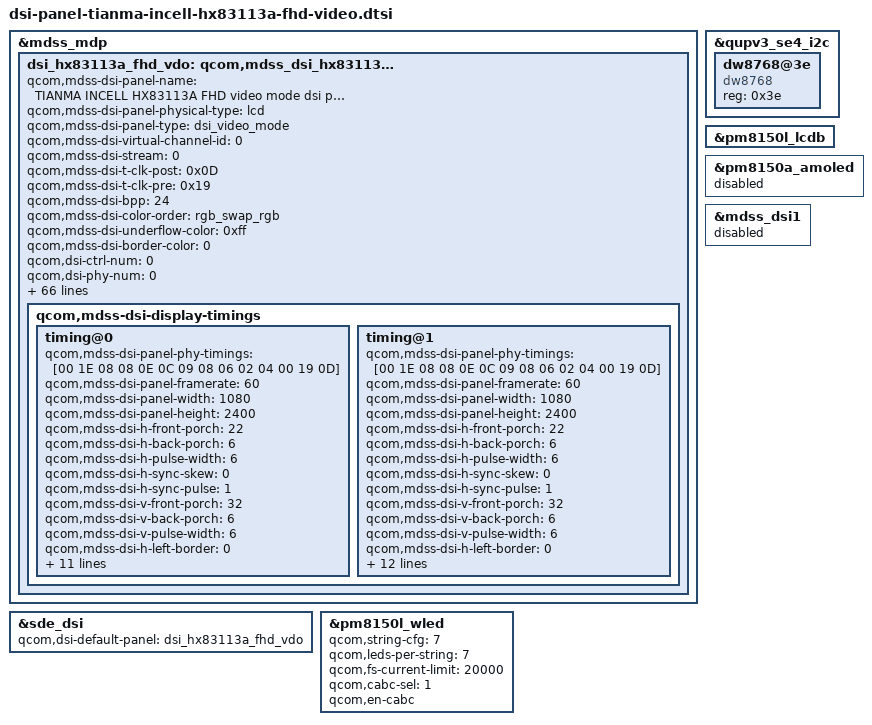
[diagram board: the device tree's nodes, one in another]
/* Copyright (c) 2014, Code Aurora Forum. All rights reserved.
 *
 * This program is free software; you can redistribute it and/or modify
 * it under the terms of the GNU General Public License version 2 and
 * only version 2 as published by the Free Software Foundation.
 *
 * This program is distributed in the hope that it will be useful,
 * but WITHOUT ANY WARRANTY; without even the implied warranty of
 * MERCHANTABILITY or FITNESS FOR A PARTICULAR PURPOSE.  See the
 * GNU General Public License for more details.
 */

&mdss_mdp {
	dsi_hx83113a_fhd_vdo: qcom,mdss_dsi_hx83113a_fhd_vdo {
		//qcom,cont-splash-enabled;
		qcom,mdss-dsi-panel-name = "TIANMA INCELL HX83113A FHD video mode dsi panel";
		//qcom,mdss-dsi-panel-controller = <&mdss_dsi0>;
		qcom,mdss-dsi-panel-physical-type = "lcd";
		qcom,mdss-dsi-panel-type = "dsi_video_mode";
		//qcom,mdss-dsi-panel-destination = "display_1";
		qcom,mdss-dsi-virtual-channel-id = <0>;
		qcom,mdss-dsi-stream = <0>;
		qcom,mdss-dsi-t-clk-post = <0x0D>;
		qcom,mdss-dsi-t-clk-pre = <0x19>;
		qcom,mdss-dsi-bpp = <24>;
		qcom,mdss-dsi-color-order = "rgb_swap_rgb";
		qcom,mdss-dsi-underflow-color = <0xff>;
		qcom,mdss-dsi-border-color = <0>;
		qcom,dsi-ctrl-num = <0>;
		qcom,dsi-phy-num = <0>;
		qcom,dsi-select-clocks = "mux_byte_clk0", "mux_pixel_clk0",
								"src_byte_clk0", "src_pixel_clk0",
								"shadow_byte_clk0", "shadow_pixel_clk0";
		//qcom,esd-check-enabled;
		qcom,mdss-dsi-traffic-mode = "non_burst_sync_pulse";
		qcom,mdss-dsi-lane-map = "lane_map_0123";
		qcom,mdss-dsi-dma-trigger = "trigger_sw";
		qcom,mdss-dsi-mdp-trigger = "none";
		qcom,mdss-dsi-bllp-eof-power-mode;
		qcom,mdss-dsi-bllp-power-mode;
		qcom,ulps-enabled;
		qcom,mdss-dsi-lane-0-state;
		qcom,mdss-dsi-lane-1-state;
		qcom,mdss-dsi-lane-2-state;
		qcom,mdss-dsi-lane-3-state;
		qcom,mdss-dsi-tx-eot-append;

		qcom,mdss-dsi-bl-min-level = <1>;
		qcom,mdss-dsi-bl-max-level = <2047>;
		qcom,mdss-dsi-bl-pmic-control-type = "bl_ctrl_wled";
		qcom,mdss-dsi-reset-sequence = <0 1>, <1 11>;
		lge,incell-panel;
		lge,panel-on-pin-seq = <0 1 5>;
		lge,panel-off-pin-seq = <0 0 1>;
		lge,mdss-dsi-lp11-off;

		//qcom,mdss-dsi-te-pin-select = <1>;
		//qcom,mdss-dsi-te-dcs-command = <1>;
		//qcom,mdss-dsi-te-check-enable;
		//qcom,mdss-dsi-te-using-te-pin;
		qcom,mdss-dsi-lp11-init;
		qcom,mdss-dsi-wr-mem-start = <0x2c>;
		qcom,mdss-dsi-wr-mem-continue = <0x3c>;

		qcom,mdss-pan-physical-width-dimension = <68>;
		qcom,mdss-pan-physical-height-dimension = <152>;

		lge,blmap-size = <256>;
		lge,blmap = <
			0 31 31 31 31 31 31 31 31 31 31 33 35 37 39 41 43 45 47 49                    // 19
			51 53 55 58 60 62 64 66 68 70 72 74 76 78 80 83 85 87 89 91                    // 39
			93 95 97 99 101 103 105 107 110 112 114 116 118 120 122 124 126 128 130 132                    // 59
			135 142 150 158 166 174 182 190 198 206 214 222 230 238 246 254 262 270 278 286                    // 79
			294 302 310 318 326 334 342 350 358 366 374 382 390 398 406 414 422 430 438 446                    // 99
			454 462 470 478 486 494 502 510 518 532 546 560 574 588 602 616 630 645 659 673                    // 119
			687 701 715 729 743 758 772 786 800 814 828 842 856 871 885 899 913 927 941 955                    // 139
			969 984 998 1012 1026 1040 1054 1068 1082 1097 1111 1125 1139 1153 1167 1181 1195 1210 1231 1253                    // 159
			1274 1296 1317 1339 1360 1382 1403 1425 1447 1468 1490 1511 1533 1554 1576 1597 1619 1641 1662 1684                    // 179
			1705 1727 1748 1770 1791 1813 1834 1856 1878 1899 1921 1942 1964 1985 2007 2028 2050 2072 2093 2115                    // 199
			2136 2158 2179 2201 2222 2244 2266 2295 2325 2354 2384 2413 2443 2473 2502 2532 2561 2591 2620 2650                    // 219
			2680 2709 2739 2768 2798 2827 2857 2887 2916 2946 2975 3005 3034 3064 3094 3123 3153 3182 3212 3241                    // 239
			3271 3301 3330 3360 3389 3419 3448 3478 3508 3537 3567 3596 3626 3655 3685 3715                    // 255
		>;

		lge,use-color-manager;
		lge,use-color-manager-oled;
		lge,color-manager-default-status = <1>;
		lge,mdss-dsi-color-manager-mode-table = <0 1>, <1 1>, <2 1>, <3 1>;
		lge,digital-gamma-absent;

		/* Screen Color Control */
		lge,rgb-lut = [
			15 01 00 00 00 00 02 BD 00
			15 01 00 00 00 00 02 C1 01
			15 01 00 00 00 00 02 BD 01
			39 01 00 00 00 00 3B C1 00 04 08 0C 10 14 18 1C 1F 23 27 2B 2F 33 37 3B 3F 43 47 4B 53 5B 62 6A 72 7A 82 8A 92 9A A1 A9 B1 B9 C1 C9 D1 D9 E0 E8 F0 F4 F6 F8 FA FB FF FF FF FF FF FF FF FF FF FF FF FF
			15 01 00 00 00 00 02 BD 02
			39 01 00 00 00 00 3B C1 00 04 08 0C 10 14 18 1C 20 24 28 2C 30 34 38 3C 40 44 48 4C 54 5C 64 6C 74 7C 84 8C 94 9C A4 AC B4 BC C4 CC D4 DC E4 EC F4 F8 FA FC FE FF FF FF FF FF FF FF FF FF FF FF FF FF
			15 01 00 00 00 00 02 BD 03
			39 01 00 00 00 00 3B C1 00 04 07 0B 0E 12 16 19 1D 21 24 28 2B 2F 33 36 3A 3E 41 45 4C 53 5B 62 69 70 78 7F 86 8D 95 9C A3 AA B2 B9 C0 C7 CF D6 DD E1 E2 E4 E6 E7 FF FF FF FF FF FF FF FF FF FF FF FF
		];
		lge,rgb-lut-state = "dsi_hs_mode";

		lge,mdss-dsi-disp-ctrl-command-1 = [
			15 01 00 00 00 00 02 CE 25
		];
		lge,mdss-dsi-disp-ctrl-command-1-state = "dsi_hs_mode";

		lge,mdss-dsi-saturation-command = [
			39 01 00 00 00 00 3D E6 40 2A 1E 00 AA 3A 11 26 00 AA DD D6 F0 D4 55 FF F0 00 00 A5 00 2A 00 00 AA 00 33 33 00 AA 00 00 00 00 AA 00 00 00 00 AA 00 00 00 00 AA DD D0 F0 FF 55 00 00 00 00 AA 66 33 2A 00 AA
		];
		lge,mdss-dsi-saturation-command-state = "dsi_hs_mode";

		lge,mdss-dsi-hue-command = [
			15 01 00 00 00 00 02 BD 00
			39 01 00 00 00 00 0E E5 06 FF FE FE FF 06 00 FE 00 FE 11 1C 05
		];
		lge,mdss-dsi-hue-command-state = "dsi_hs_mode";

		lge,mdss-dsi-cm-natural = [
			15 01 00 00 00 00 02 BD 00
			39 01 00 00 00 00 0E E5 06 FF FE FE FF 06 00 FE 00 FE 11 1C 05
			39 01 00 00 00 00 3D E6 40 2A 1E 00 AA 3A 11 26 00 AA DD D6 F0 D4 55 FF F0 00 00 A5 00 2A 00 00 AA 00 33 33 00 AA 00 00 00 00 AA 00 00 00 00 AA 00 00 00 00 AA DD D0 F0 FF 55 00 00 00 00 AA 66 33 2A 00 AA
			15 01 00 00 00 00 02 BD 00
			15 01 00 00 00 00 02 C1 01
			15 01 00 00 00 00 02 BD 01
			39 01 00 00 00 00 3B C1 00 04 08 0C 10 14 18 1C 1F 23 27 2B 2F 33 37 3B 3F 43 47 4B 53 5B 62 6A 72 7A 82 8A 92 9A A1 A9 B1 B9 C1 C9 D1 D9 E0 E8 F0 F4 F6 F8 FA FB FF FF FF FF FF FF FF FF FF FF FF FF
			15 01 00 00 00 00 02 BD 02
			39 01 00 00 00 00 3B C1 00 04 08 0C 10 14 18 1C 20 24 28 2C 30 34 38 3C 40 44 48 4C 54 5C 64 6C 74 7C 84 8C 94 9C A4 AC B4 BC C4 CC D4 DC E4 EC F4 F8 FA FC FE FF FF FF FF FF FF FF FF FF FF FF FF FF
			15 01 00 00 00 00 02 BD 03
			39 01 00 00 00 00 3B C1 00 04 07 0B 0E 12 16 19 1D 21 24 28 2B 2F 33 36 3A 3E 41 45 4C 53 5B 62 69 70 78 7F 86 8D 95 9C A3 AA B2 B9 C0 C7 CF D6 DD E1 E2 E4 E6 E7 FF FF FF FF FF FF FF FF FF FF FF FF
		];
		lge,mdss-dsi-cm-natural-state = "dsi_hs_mode";

		lge,mdss-dsi-cm-vivid = [
			15 01 00 00 00 00 02 BD 00
			39 01 00 00 00 00 0E E5 06 FF FE FE FF 06 00 FE 00 FE 11 1C 05
			39 01 00 00 00 00 3D E6 70 4E 30 00 AA 60 40 30 00 AA 60 60 38 00 AA 60 60 20 00 AA 60 7A 28 00 AA 40 73 50 00 AA 10 20 10 00 AA 08 10 08 00 AA 07 0E 07 00 AA E5 E0 F8 FF 55 18 30 18 00 AA 80 78 42 00 AA
			15 01 00 00 00 00 02 BD 00
			15 01 00 00 00 00 02 C1 01
			39 01 00 00 00 00 02 BD 01
			39 01 00 00 00 00 3B C1 00 04 08 0C 10 14 18 1C 20 24 28 2C 30 34 38 3C 3F 43 47 4B 53 5B 63 6B 73 7B 83 8B 93 9B A3 AB B3 BB C2 CA D2 DA E2 EA F2 F6 F8 FA FC FD FF FF FF FF FF FF FF FF FF FF FF FF
			39 01 00 00 00 00 02 BD 02
			39 01 00 00 00 00 3B C1 00 04 08 0C 10 14 18 1C 20 24 28 2C 30 34 38 3C 40 44 48 4C 54 5C 64 6C 74 7C 84 8C 94 9C A4 AC B4 BC C4 CC D4 DC E4 EC F4 F8 FA FC FE FF FF FF FF FF FF FF FF FF FF FF FF FF
			39 01 00 00 00 00 02 BD 03
			39 01 00 00 00 00 3B C1 00 04 08 0B 0F 13 17 1B 1E 22 26 2A 2E 32 35 39 3D 41 45 48 50 58 5F 67 6F 76 7E 85 8D 95 9C A4 AC B3 BB C2 CA D2 D9 E1 E9 EC EE F0 F2 F3 FF FF FF FF FF FF FF FF FF FF FF FF
		];
		lge,mdss-dsi-cm-vivid-state = "dsi_hs_mode";

		/* Video Enahnacement */
		lge,mdss-dsi-ve-on-command = [
			39 01 00 00 00 00 3D E6 70 4E 30 00 AA 60 40 30 00 AA 60 60 38 00 AA 60 60 20 00 AA 60 7A 28 00 AA 40 73 50 00 AA 10 20 10 00 AA 08 10 08 00 AA 07 0E 07 00 AA E5 E0 F8 FF 55 18 30 18 00 AA 80 78 42 00 AA
			15 01 00 00 00 00 02 CE 25
			15 01 00 00 00 00 02 BD 02
			39 01 00 00 00 00 24 E4 00 3F 04 00 00 04 40 00 40 80 00 00 00 90 03 00 08 00 10 08 04 04 3B 10 38 10 01 01 01 01 00 00 00 01 14
			15 01 00 00 00 00 02 BD 00
			39 01 00 00 00 00 05 E4 3D 03 41 90
		];
		lge,mdss-dsi-ve-on-command-state = "dsi_hs_mode";

		lge,mdss-dsi-ve-off-command = [
			15 01 00 00 00 00 02 BD 00
			39 01 00 00 00 00 02 E4 2D
		];
		lge,mdss-dsi-ve-off-command-state = "dsi_hs_mode";

		qcom,mdss-dsi-display-timings {
			timing@0{
				qcom,mdss-dsi-panel-phy-timings = [00 1E 08 08 0E 0C 09 08 06 02 04 00 19 0D];
				qcom,mdss-dsi-panel-framerate = <60>;
				qcom,mdss-dsi-panel-width = <1080>;
				qcom,mdss-dsi-panel-height = <2400>;
				qcom,mdss-dsi-h-front-porch = <22>;
				qcom,mdss-dsi-h-back-porch = <6>;
				qcom,mdss-dsi-h-pulse-width = <6>;
				qcom,mdss-dsi-h-sync-skew = <0>;
				qcom,mdss-dsi-h-sync-pulse = <1>;
				qcom,mdss-dsi-v-front-porch = <32>;
				qcom,mdss-dsi-v-back-porch = <6>;
				qcom,mdss-dsi-v-pulse-width = <6>;
				qcom,mdss-dsi-h-left-border = <0>;
				qcom,mdss-dsi-h-right-border = <0>;
				qcom,mdss-dsi-v-top-border = <0>;
				qcom,mdss-dsi-v-bottom-border = <0>;
				qcom,display-topology = <1 0 1>;
				qcom,default-topology-index = <0>;

				qcom,mdss-dsi-on-command = [
					39 01 00 00 00 00 04 // 10
					B9 83 11 3A

					15 01 00 00 00 00 02 // 11
					BB 03

					39 01 00 00 00 00 0C // 12
					B1 4C 1F 1F 85 80 BC 9E 3C 1E 01 01

					39 01 00 00 00 00 11 // 13
					B2 00 33 88 90 60 00 0A 1E 00 04 00 D2 11 11 00 00

					39 01 00 00 00 00 1E // 14
					B4 9D 28 9D 28 9D 28 06 CA 06 CA 06 CA 06 CA 00 00 08 09 00 14 00 0D 07 0E 00 00 00 00 8D

					15 01 00 00 00 00 02 // 15
					E9 C8

					15 01 00 00 00 00 02 // 16
					BF 04

					15 01 00 00 00 00 02 // 17
					E9 3F

					39 01 00 00 00 00 09 // 18
					C0 23 23 44 FF 12 1A 00 03

					// 19 deleted

					39 01 00 00 00 00 06 // 20
					C9 00 00 09 60 00

					39 01 00 00 00 00 08 // 21
					CB 5F 19 10 06 00 EE 04

					15 01 00 00 00 00 02 // 22
					CC 0A

					39 01 00 00 00 00 27 // 23
					D3 81 08 01 01 00 08 01 01 07 01 09 09 09 09 09 09 20 04 32 10 08 00 08 32 10 07 00 07 32 10 07 00 07 00 00 0C 09 6C

					39 01 00 00 00 00 31 // 24
					D5 18 18 18 18 18 18 18 18 18 18 18 18 2F 2F 30 30 31 31 32 32 33 33 34 34 41 41 21 20 03 02 07 06 01 00 05 04 18 18 41 41 18 18 18 18 18 18 40 40

					39 01 00 00 00 00 31 // 25
					D6 18 18 18 18 18 18 18 18 18 18 18 18 2F 2F 30 30 31 31 32 32 33 33 34 34 41 41 21 20 04 05 00 01 06 07 02 03 41 41 18 18 18 18 18 18 18 18 40 40

					39 01 00 00 00 00 25 // 26
					D8 AA AF FF AA AA AB AA AF FF AA AA AB AA AF FF AF FB AA AA AF FF AF FB AA AA AA AA AA AA AA AA AA AA AA AA AA

					39 01 00 00 00 00 3E // 27
					DF 07 00 00 00 FF FF FF A5 E2 4E 74 56 2A EE 44 67 A5 E2 4E 74 56 2A EE 44 67 A5 E2 4E 74 56 2A EE 44 67 A5 E2 4E 74 56 2A EE 44 67 E1 AC 86 B3 1A CE 6A 38 AB E1 AC 86 B3 1A CE 6A 38 AB

					15 01 00 00 00 00 02 // 28
					E9 CB

					15 01 00 00 00 00 02 // 29
					E4 00

					15 01 00 00 00 00 02 // 30
					E9 3F

					39 01 00 00 00 00 1A // 31
					E7 36 2A 08 08 25 72 24 72 00 AA 02 02 00 00 02 02 12 05 FF FF 24 72 00 AA 08

					15 01 00 00 00 00 02 // 32
					E9 DD

					15 01 00 00 00 00 02 // 33
					E7 17

					15 01 00 00 00 00 02 // 34
					E9 3F

					15 01 00 00 00 00 02 // 35
					E9 C4

					39 01 00 00 00 00 03 // 36
					D1 0C DD

					15 01 00 00 00 00 02 // 37
					E9 3F

					15 01 00 00 00 00 02 // 38
					BD 01

					39 01 00 00 00 00 04 // 39
					B1 B6 11 61

					39 01 00 00 00 00 19 // 40
					D8 AA A0 00 00 00 A0 AA A0 00 00 00 A0 AA A0 00 00 00 A0 AA A0 00 00 00 A0

					39 01 00 00 00 00 09 // 41
					E7 02 70 2C 01 2E 07 28 08

					15 01 00 00 00 00 02 // 42
					E9 CC

					15 01 00 00 00 00 02 // 43
					E7 02

					15 01 00 00 00 00 02 // 44
					E9 3F

					15 01 00 00 00 00 02 // 45
					BD 02

					39 01 00 00 00 00 03 // 46
					B1 27 27

					39 01 00 00 00 00 04 // 47
					B4 12 11 89

					39 01 00 00 00 00 0D // 48
					D8 AA AF FF EA AA AE AA AF FF EA AA AE

					39 01 00 00 00 00 14 // 49
					E7 02 02 02 00 CA 01 03 01 03 01 03 02 20 08 40 0B 0A 00 00

					15 01 00 00 00 00 02 // 50
					E9 E2

					15 01 00 00 00 00 02 // 51
					E7 18

					15 01 00 00 00 00 02 // 52
					E9 3F

					15 01 00 00 00 00 02 // 53
					BD 03

					39 01 00 00 00 00 19 // 54
					D8 AA AA AA AA AA AB AA AA AA AA AA AB AA AF FF EA AA AE AA AF FF EA AA AE

					15 01 00 00 00 00 02 // 55
					BD 00

					15 01 00 00 00 00 02 // Notch IP Circle
					BD 00

					39 01 00 00 00 00 10
					D0 35 00 00 4A 00 00 00 00 00 02 00 01 F8 00 1B

					15 01 00 00 00 00 02
					BD 03

					15 01 00 00 00 00 02
					D0 1F

					15 01 00 00 00 00 02
					D0 07

					15 01 00 00 00 00 02
					D0 00

					15 01 00 00 00 00 02
					D0 A4

					15 01 00 00 00 00 02
					D0 A4

					15 01 00 00 00 00 02
					D0 A4

					15 01 00 00 00 00 02
					D0 C0

					15 01 00 00 00 00 02
					D0 C0

					15 01 00 00 00 00 02
					D0 C0

					15 01 00 00 00 00 02
					D0 C0

					15 01 00 00 00 00 02
					D0 1C

					15 01 00 00 00 00 02
					D0 04

					15 01 00 00 00 00 02
					D0 0C

					15 01 00 00 00 00 02
					D0 40

					15 01 00 00 00 00 02
					D0 40

					15 01 00 00 00 00 02
					D0 80

					15 01 00 00 00 00 02
					D0 C0

					15 01 00 00 00 00 02
					D0 19

					15 01 00 00 00 00 02
					D0 02

					15 01 00 00 00 00 02
					D0 16

					15 01 00 00 00 00 02
					D0 40

					15 01 00 00 00 00 02
					D0 C0

					15 01 00 00 00 00 02
					D0 16

					15 01 00 00 00 00 02
					D0 03

					15 01 00 00 00 00 02
					D0 1A

					15 01 00 00 00 00 02
					D0 40

					15 01 00 00 00 00 02
					D0 80

					15 01 00 00 00 00 02
					D0 F0

					15 01 00 00 00 00 02
					D0 14

					15 01 00 00 00 00 02
					D0 02

					15 01 00 00 00 00 02
					D0 20

					15 01 00 00 00 00 02
					D0 80

					15 01 00 00 00 00 02
					D0 F0

					15 01 00 00 00 00 02
					D0 13

					15 01 00 00 00 00 02
					D0 01

					15 01 00 00 00 00 02
					D0 24

					15 01 00 00 00 00 02
					D0 A4

					15 01 00 00 00 00 02
					D0 11

					15 01 00 00 00 00 02
					D0 02

					15 01 00 00 00 00 02
					D0 26

					15 01 00 00 00 00 02
					D0 40

					15 01 00 00 00 00 02
					D0 C0

					15 01 00 00 00 00 02
					D0 10

					15 01 00 00 00 00 02
					D0 01

					15 01 00 00 00 00 02
					D0 2A

					15 01 00 00 00 00 02
					D0 A4

					15 01 00 00 00 00 02
					D0 0E

					15 01 00 00 00 00 02
					D0 02

					15 01 00 00 00 00 02
					D0 2C

					15 01 00 00 00 00 02
					D0 40

					15 01 00 00 00 00 02
					D0 C0

					15 01 00 00 00 00 02
					D0 0D

					15 01 00 00 00 00 02
					D0 02

					15 01 00 00 00 00 02
					D0 2E

					15 01 00 00 00 00 02
					D0 40

					15 01 00 00 00 00 02
					D0 C0

					15 01 00 00 00 00 02
					D0 0C

					15 01 00 00 00 00 02
					D0 02

					15 01 00 00 00 00 02
					D0 30

					15 01 00 00 00 00 02
					D0 40

					15 01 00 00 00 00 02
					D0 C0

					15 01 00 00 00 00 02
					D0 0B

					15 01 00 00 00 00 02
					D0 01

					15 01 00 00 00 00 02
					D0 34

					15 01 00 00 00 00 02
					D0 C0

					15 01 00 00 00 00 02
					D0 0A

					15 01 00 00 00 00 02
					D0 02

					15 01 00 00 00 00 02
					D0 34

					15 01 00 00 00 00 02
					D0 40

					15 01 00 00 00 00 02
					D0 C0

					15 01 00 00 00 00 02
					D0 0A

					15 01 00 00 00 00 02
					D0 01

					15 01 00 00 00 00 02
					D0 36

					15 01 00 00 00 00 02
					D0 40

					15 01 00 00 00 00 02
					D0 09

					15 01 00 00 00 00 02
					D0 01

					15 01 00 00 00 00 02
					D0 38

					15 01 00 00 00 00 02
					D0 40

					15 01 00 00 00 00 02
					D0 08

					15 01 00 00 00 00 02
					D0 01

					15 01 00 00 00 00 02
					D0 3A

					15 01 00 00 00 00 02
					D0 C0

					15 01 00 00 00 00 02
					D0 08

					15 01 00 00 00 00 02
					D0 01

					15 01 00 00 00 00 02
					D0 3A

					15 01 00 00 00 00 02
					D0 40

					15 01 00 00 00 00 02
					D0 07

					15 01 00 00 00 00 02
					D0 01

					15 01 00 00 00 00 02
					D0 3C

					15 01 00 00 00 00 02
					D0 40

					15 01 00 00 00 00 02
					D0 06

					15 01 00 00 00 00 02
					D0 01

					15 01 00 00 00 00 02
					D0 3E

					15 01 00 00 00 00 02
					D0 4A

					15 01 00 00 00 00 02
					D0 05

					15 01 00 00 00 00 02
					D0 02

					15 01 00 00 00 00 02
					D0 3E

					15 01 00 00 00 00 02
					D0 40

					15 01 00 00 00 00 02
					D0 A4

					15 01 00 00 00 00 02
					D0 05

					15 01 00 00 00 00 02
					D0 01

					15 01 00 00 00 00 02
					D0 40

					15 01 00 00 00 00 02
					D0 40

					15 01 00 00 00 00 02
					D0 04

					15 01 00 00 00 00 02
					D0 02

					15 01 00 00 00 00 02
					D0 40

					15 01 00 00 00 00 02
					D0 40

					15 01 00 00 00 00 02
					D0 C0

					15 01 00 00 00 00 02
					D0 04

					15 01 00 00 00 00 02
					D0 01

					15 01 00 00 00 00 02
					D0 42

					15 01 00 00 00 00 02
					D0 80

					15 01 00 00 00 00 02
					D0 04

					15 01 00 00 00 00 02
					D0 01

					15 01 00 00 00 00 02
					D0 42

					15 01 00 00 00 00 02
					D0 40

					15 01 00 00 00 00 02
					D0 03

					15 01 00 00 00 00 02
					D0 01

					15 01 00 00 00 00 02
					D0 44

					15 01 00 00 00 00 02
					D0 C0

					15 01 00 00 00 00 02
					D0 03

					15 01 00 00 00 00 02
					D0 01

					15 01 00 00 00 00 02
					D0 44

					15 01 00 00 00 00 02
					D0 40

					15 01 00 00 00 00 02
					D0 03

					15 01 00 00 00 00 02
					D0 00

					15 01 00 00 00 00 02
					D0 46

					15 01 00 00 00 00 02
					D0 02

					15 01 00 00 00 00 02
					D0 01

					15 01 00 00 00 00 02
					D0 46

					15 01 00 00 00 00 02
					D0 C0

					15 01 00 00 00 00 02
					D0 02

					15 01 00 00 00 00 02
					D0 01

					15 01 00 00 00 00 02
					D0 46

					15 01 00 00 00 00 02
					D0 80

					15 01 00 00 00 00 02
					D0 02

					15 01 00 00 00 00 02
					D0 00

					15 01 00 00 00 00 02
					D0 48

					15 01 00 00 00 00 02
					D0 01

					15 01 00 00 00 00 02
					D0 01

					15 01 00 00 00 00 02
					D0 48

					15 01 00 00 00 00 02
					D0 C0

					15 01 00 00 00 00 02
					D0 01

					15 01 00 00 00 00 02
					D0 01

					15 01 00 00 00 00 02
					D0 48

					15 01 00 00 00 00 02
					D0 C0

					15 01 00 00 00 00 02
					D0 01

					15 01 00 00 00 00 02
					D0 01

					15 01 00 00 00 00 02
					D0 48

					15 01 00 00 00 00 02
					D0 C0

					15 01 00 00 00 00 02
					D0 01

					15 01 00 00 00 00 02
					D0 01

					15 01 00 00 00 00 02
					D0 48

					15 01 00 00 00 00 02
					D0 A4

					15 01 00 00 00 00 02
					D0 01

					15 01 00 00 00 00 02
					D0 01

					15 01 00 00 00 00 02
					D0 48

					15 01 00 00 00 00 02
					D0 A4

					15 01 00 00 00 00 02
					D0 01

					15 01 00 00 00 00 02
					D0 01

					15 01 00 00 00 00 02
					D0 48

					15 01 00 00 00 00 02
					D0 80

					15 01 00 00 00 00 02
					D0 01

					15 01 00 00 00 00 02
					D0 01

					15 01 00 00 00 00 02
					D0 48

					15 01 00 00 00 00 02
					D0 80

					15 01 00 00 00 00 02
					D0 01

					15 01 00 00 00 00 02
					D0 01

					15 01 00 00 00 00 02
					D0 48

					15 01 00 00 00 00 02
					D0 80

					15 01 00 00 00 00 02
					D0 01

					15 01 00 00 00 00 02
					D0 01

					15 01 00 00 00 00 02
					D0 48

					15 01 00 00 00 00 02
					D0 A4

					15 01 00 00 00 00 02
					D0 01

					15 01 00 00 00 00 02
					D0 01

					15 01 00 00 00 00 02
					D0 48

					15 01 00 00 00 00 02
					D0 A4

					15 01 00 00 00 00 02
					D0 01

					15 01 00 00 00 00 02
					D0 01

					15 01 00 00 00 00 02
					D0 48

					15 01 00 00 00 00 02
					D0 A4

					15 01 00 00 00 00 02
					D0 01

					15 01 00 00 00 00 02
					D0 01

					15 01 00 00 00 00 02
					D0 48

					15 01 00 00 00 00 02
					D0 C0

					15 01 00 00 00 00 02
					D0 01

					15 01 00 00 00 00 02
					D0 01

					15 01 00 00 00 00 02
					D0 48

					15 01 00 00 00 00 02
					D0 C0

					15 01 00 00 00 00 02
					D0 01

					15 01 00 00 00 00 02
					D0 01

					15 01 00 00 00 00 02
					D0 48

					15 01 00 00 00 00 02
					D0 C0

					15 01 00 00 00 00 02
					D0 02

					15 01 00 00 00 00 02
					D0 00

					15 01 00 00 00 00 02
					D0 48

					15 01 00 00 00 00 02
					D0 02

					15 01 00 00 00 00 02
					D0 01

					15 01 00 00 00 00 02
					D0 46

					15 01 00 00 00 00 02
					D0 80

					15 01 00 00 00 00 02
					D0 02

					15 01 00 00 00 00 02
					D0 01

					15 01 00 00 00 00 02
					D0 46

					15 01 00 00 00 00 02
					D0 C0

					15 01 00 00 00 00 02
					D0 03

					15 01 00 00 00 00 02
					D0 00

					15 01 00 00 00 00 02
					D0 46

					15 01 00 00 00 00 02
					D0 03

					15 01 00 00 00 00 02
					D0 01

					15 01 00 00 00 00 02
					D0 44

					15 01 00 00 00 00 02
					D0 40

					15 01 00 00 00 00 02
					D0 03

					15 01 00 00 00 00 02
					D0 01

					15 01 00 00 00 00 02
					D0 44

					15 01 00 00 00 00 02
					D0 A4

					15 01 00 00 00 00 02
					D0 04

					15 01 00 00 00 00 02
					D0 01

					15 01 00 00 00 00 02
					D0 42

					15 01 00 00 00 00 02
					D0 40

					15 01 00 00 00 00 02
					D0 04

					15 01 00 00 00 00 02
					D0 01

					15 01 00 00 00 00 02
					D0 42

					15 01 00 00 00 00 02
					D0 80

					15 01 00 00 00 00 02
					D0 04

					15 01 00 00 00 00 02
					D0 01

					15 01 00 00 00 00 02
					D0 42

					15 01 00 00 00 00 02
					D0 F0

					15 01 00 00 00 00 02
					D0 05

					15 01 00 00 00 00 02
					D0 01

					15 01 00 00 00 00 02
					D0 40

					15 01 00 00 00 00 02
					D0 80

					15 01 00 00 00 00 02
					D0 05

					15 01 00 00 00 00 02
					D0 01

					15 01 00 00 00 00 02
					D0 40

					15 01 00 00 00 00 02
					D0 F0

					15 01 00 00 00 00 02
					D0 06

					15 01 00 00 00 00 02
					D0 01

					15 01 00 00 00 00 02
					D0 3E

					15 01 00 00 00 00 02
					D0 80

					15 01 00 00 00 00 02
					D0 07

					15 01 00 00 00 00 02
					D0 01

					15 01 00 00 00 00 02
					D0 3C

					15 01 00 00 00 00 02
					D0 40

					15 01 00 00 00 00 02
					D0 07

					15 01 00 00 00 00 02
					D0 01

					15 01 00 00 00 00 02
					D0 3C

					15 01 00 00 00 00 02
					D0 C0

					15 01 00 00 00 00 02
					D0 08

					15 01 00 00 00 00 02
					D0 01

					15 01 00 00 00 00 02
					D0 3A

					15 01 00 00 00 00 02
					D0 80

					15 01 00 00 00 00 02
					D0 09

					15 01 00 00 00 00 02
					D0 01

					15 01 00 00 00 00 02
					D0 38

					15 01 00 00 00 00 02
					D0 40

					15 01 00 00 00 00 02
					D0 09

					15 01 00 00 00 00 02
					D0 02

					15 01 00 00 00 00 02
					D0 36

					15 01 00 00 00 00 02
					D0 40

					15 01 00 00 00 00 02
					D0 C0

					15 01 00 00 00 00 02
					D0 0A

					15 01 00 00 00 00 02
					D0 02

					15 01 00 00 00 00 02
					D0 34

					15 01 00 00 00 00 02
					D0 40

					15 01 00 00 00 00 02
					D0 80

					15 01 00 00 00 00 02
					D0 0B

					15 01 00 00 00 00 02
					D0 01

					15 01 00 00 00 00 02
					D0 34

					15 01 00 00 00 00 02
					D0 C0

					15 01 00 00 00 00 02
					D0 0C

					15 01 00 00 00 00 02
					D0 01 //

					15 01 00 00 00 00 02
					D0 32

					15 01 00 00 00 00 02
					D0 C0

					15 01 00 00 00 00 02
					D0 0D

					15 01 00 00 00 00 02
					D0 02

					15 01 00 00 00 00 02
					D0 2E

					15 01 00 00 00 00 02
					D0 40

					15 01 00 00 00 00 02
					D0 C0

					15 01 00 00 00 00 02
					D0 0E

					15 01 00 00 00 00 02
					D0 02

					15 01 00 00 00 00 02
					D0 2C

					15 01 00 00 00 00 02
					D0 40

					15 01 00 00 00 00 02
					D0 C0

					15 01 00 00 00 00 02
					D0 10

					15 01 00 00 00 00 02
					D0 01

					15 01 00 00 00 00 02
					D0 2A

					15 01 00 00 00 00 02
					D0 80

					15 01 00 00 00 00 02
					D0 11

					15 01 00 00 00 00 02
					D0 02

					15 01 00 00 00 00 02
					D0 26

					15 01 00 00 00 00 02
					D0 40

					15 01 00 00 00 00 02
					D0 C0

					15 01 00 00 00 00 02
					D0 13

					15 01 00 00 00 00 02
					D0 01

					15 01 00 00 00 00 02
					D0 24

					15 01 00 00 00 00 02
					D0 80

					15 01 00 00 00 00 02
					D0 14

					15 01 00 00 00 00 02
					D0 02 //

					15 01 00 00 00 00 02
					D0 20

					15 01 00 00 00 00 02
					D0 80

					15 01 00 00 00 00 02
					D0 F0

					15 01 00 00 00 00 02
					D0 16

					15 01 00 00 00 00 02
					D0 02

					15 01 00 00 00 00 02
					D0 1C

					15 01 00 00 00 00 02
					D0 80

					15 01 00 00 00 00 02
					D0 F0

					15 01 00 00 00 00 02
					D0 19

					15 01 00 00 00 00 02
					D0 02

					15 01 00 00 00 00 02
					D0 16

					15 01 00 00 00 00 02
					D0 40

					15 01 00 00 00 00 02
					D0 C0

					15 01 00 00 00 00 02
					D0 1C

					15 01 00 00 00 00 02
					D0 03

					15 01 00 00 00 00 02
					D0 0E

					15 01 00 00 00 00 02
					D0 40

					15 01 00 00 00 00 02
					D0 80

					15 01 00 00 00 00 02
					D0 C0

					15 01 00 00 00 00 02
					D0 1F

					15 01 00 00 00 00 02
					D0 07

					15 01 00 00 00 00 02
					D0 00

					15 01 00 00 00 00 02
					D0 80

					15 01 00 00 00 00 02
					D0 80

					15 01 00 00 00 00 02
					D0 A4

					15 01 00 00 00 00 02
					D0 A4

					15 01 00 00 00 00 02
					D0 C0

					15 01 00 00 00 00 02
					D0 C0

					15 01 00 00 00 00 02
					D0 C0

					15 01 00 00 00 00 02
					BD 00

					15 01 00 00 00 00 02
					D0 31

					05 01 00 00 64 00 01 // Sleep out
					11

					05 01 00 00 0A 00 01 // Display on
					29

					39 01 00 00 00 00 03 // 56 - Set CABC Manual brightness
					51 0F FF

					39 01 00 00 00 00 03 // 57 - Set CABC Minimum brightness
					5E 00 3D

					39 01 00 00 00 00 06 // 58 - Set PWM Frequency to 20kHz
					C9 00 1E 0E B0 01

					15 01 00 00 00 00 02 // 59 - Set CABC mode to UI mode
					55 01

					15 01 00 00 00 00 02 // 59 - Set to Bank3
					BD 03

					39 01 00 00 00 00 0B // 57 - PWM duty is 70% for UI mode
					E4 CD CD CD A7 A7 A7 C3 C3 C3 EA

					15 01 00 00 00 00 02 // 59 - Set to Bank0
					BD 00

					15 01 00 00 00 00 02 // 60 - Enable Backlight Control
					53 24
				];
				qcom,mdss-dsi-on-command-state = "dsi_lp_mode";

				qcom,mdss-dsi-off-command = [
					05 01 00 00 14 00 01 // Display off
					28

					05 01 00 00 46 00 01 // Sleep in
					10
				];
				qcom,mdss-dsi-off-command-state = "dsi_hs_mode";
			};

			timing@1{
				qcom,mdss-dsi-panel-phy-timings = [00 1E 08 08 0E 0C 09 08 06 02 04 00 19 0D];
				qcom,mdss-dsi-panel-framerate = <60>;
				qcom,mdss-dsi-panel-width = <1080>;
				qcom,mdss-dsi-panel-height = <2400>;
				qcom,mdss-dsi-h-front-porch = <22>;
				qcom,mdss-dsi-h-back-porch = <6>;
				qcom,mdss-dsi-h-pulse-width = <6>;
				qcom,mdss-dsi-h-sync-skew = <0>;
				qcom,mdss-dsi-h-sync-pulse = <1>;
				qcom,mdss-dsi-v-front-porch = <32>;
				qcom,mdss-dsi-v-back-porch = <6>;
				qcom,mdss-dsi-v-pulse-width = <6>;
				qcom,mdss-dsi-h-left-border = <0>;
				qcom,mdss-dsi-h-right-border = <0>;
				qcom,mdss-dsi-v-top-border = <0>;
				qcom,mdss-dsi-v-bottom-border = <0>;
				qcom,display-topology = <1 0 1>;
				qcom,default-topology-index = <0>;
				lge,mdss-dsi-panel-framerate-div = <2>;

				qcom,mdss-dsi-on-command = [
					39 01 00 00 00 00 04 // 10
					B9 83 11 3A

					15 01 00 00 00 00 02 // 11
					BB 03

					39 01 00 00 00 00 0C // 12
					B1 4C 1F 1F 85 80 BC 9E 3C 1E 01 01

					39 01 00 00 00 00 11 // 13
					B2 00 33 88 90 60 00 0A 1E 00 04 00 D2 11 11 00 00

					39 01 00 00 00 00 1E // 14
					B4 9D 28 9D 28 9D 28 06 CA 06 CA 06 CA 06 CA 00 00 08 09 00 14 00 0D 07 0E 00 00 00 00 8D

					15 01 00 00 00 00 02 // 15
					E9 C8

					15 01 00 00 00 00 02 // 16
					BF 04

					15 01 00 00 00 00 02 // 17
					E9 3F

					39 01 00 00 00 00 09 // 18
					C0 23 23 44 FF 12 1A 00 03

					// 19 deleted

					39 01 00 00 00 00 06 // 20
					C9 00 00 09 60 00

					39 01 00 00 00 00 08 // 21
					CB 5F 19 10 06 00 EE 04

					15 01 00 00 00 00 02 // 22
					CC 0A

					39 01 00 00 00 00 27 // 23
					D3 81 08 01 01 00 08 01 01 07 01 09 09 09 09 09 09 20 04 32 10 08 00 08 32 10 07 00 07 32 10 07 00 07 00 00 0C 09 6C

					39 01 00 00 00 00 31 // 24
					D5 18 18 18 18 18 18 18 18 18 18 18 18 2F 2F 30 30 31 31 32 32 33 33 34 34 41 41 21 20 03 02 07 06 01 00 05 04 18 18 41 41 18 18 18 18 18 18 40 40

					39 01 00 00 00 00 31 // 25
					D6 18 18 18 18 18 18 18 18 18 18 18 18 2F 2F 30 30 31 31 32 32 33 33 34 34 41 41 21 20 04 05 00 01 06 07 02 03 41 41 18 18 18 18 18 18 18 18 40 40

					39 01 00 00 00 00 25 // 26
					D8 AA AF FF AA AA AB AA AF FF AA AA AB AA AF FF AF FB AA AA AF FF AF FB AA AA AA AA AA AA AA AA AA AA AA AA AA

					39 01 00 00 00 00 3E // 27
					DF 07 00 00 00 FF FF FF A5 E2 4E 74 56 2A EE 44 67 A5 E2 4E 74 56 2A EE 44 67 A5 E2 4E 74 56 2A EE 44 67 A5 E2 4E 74 56 2A EE 44 67 E1 AC 86 B3 1A CE 6A 38 AB E1 AC 86 B3 1A CE 6A 38 AB

					15 01 00 00 00 00 02 // 28
					E9 CB

					15 01 00 00 00 00 02 // 29
					E4 00

					15 01 00 00 00 00 02 // 30
					E9 3F

					39 01 00 00 00 00 1A // 31
					E7 36 2A 08 08 25 72 24 72 00 AA 02 02 00 00 02 02 12 05 FF FF 24 72 00 AA 08

					15 01 00 00 00 00 02 // 32
					E9 DD

					15 01 00 00 00 00 02 // 33
					E7 17

					15 01 00 00 00 00 02 // 34
					E9 3F

					15 01 00 00 00 00 02 // 35
					E9 C4

					39 01 00 00 00 00 03 // 36
					D1 0C DD

					15 01 00 00 00 00 02 // 37
					E9 3F

					15 01 00 00 00 00 02 // 38
					BD 01

					39 01 00 00 00 00 04 // 39
					B1 B6 11 61

					39 01 00 00 00 00 19 // 40
					D8 AA A0 00 00 00 A0 AA A0 00 00 00 A0 AA A0 00 00 00 A0 AA A0 00 00 00 A0

					39 01 00 00 00 00 09 // 41
					E7 02 70 2C 01 2E 07 28 08

					15 01 00 00 00 00 02 // 42
					E9 CC

					15 01 00 00 00 00 02 // 43
					E7 02

					15 01 00 00 00 00 02 // 44
					E9 3F

					15 01 00 00 00 00 02 // 45
					BD 02

					39 01 00 00 00 00 03 // 46
					B1 27 27

					39 01 00 00 00 00 04 // 47
					B4 12 11 89

					39 01 00 00 00 00 0D // 48
					D8 AA AF FF EA AA AE AA AF FF EA AA AE

					39 01 00 00 00 00 14 // 49
					E7 02 02 02 00 CA 01 03 01 03 01 03 02 20 08 40 0B 0A 00 00

					15 01 00 00 00 00 02 // 50
					E9 E2

					15 01 00 00 00 00 02 // 51
					E7 18

					15 01 00 00 00 00 02 // 52
					E9 3F

					15 01 00 00 00 00 02 // 53
					BD 03

					39 01 00 00 00 00 19 // 54
					D8 AA AA AA AA AA AB AA AA AA AA AA AB AA AF FF EA AA AE AA AF FF EA AA AE

					15 01 00 00 00 00 02 // 55
					BD 00

					15 01 00 00 00 00 02 // Notch IP Circle
					BD 00

					39 01 00 00 00 00 10
					D0 35 00 00 4A 00 00 00 00 00 02 00 01 F8 00 1B

					15 01 00 00 00 00 02
					BD 03

					15 01 00 00 00 00 02
					D0 1F

					15 01 00 00 00 00 02
					D0 07

					15 01 00 00 00 00 02
					D0 00

					15 01 00 00 00 00 02
					D0 A4

					15 01 00 00 00 00 02
					D0 A4

					15 01 00 00 00 00 02
					D0 A4

					15 01 00 00 00 00 02
					D0 C0

					15 01 00 00 00 00 02
					D0 C0

					15 01 00 00 00 00 02
					D0 C0

					15 01 00 00 00 00 02
					D0 C0

					15 01 00 00 00 00 02
					D0 1C

					15 01 00 00 00 00 02
					D0 04

					15 01 00 00 00 00 02
					D0 0C

					15 01 00 00 00 00 02
					D0 40

					15 01 00 00 00 00 02
					D0 40

					15 01 00 00 00 00 02
					D0 80

					15 01 00 00 00 00 02
					D0 C0

					15 01 00 00 00 00 02
					D0 19

					15 01 00 00 00 00 02
					D0 02

					15 01 00 00 00 00 02
					D0 16

					15 01 00 00 00 00 02
					D0 40

					15 01 00 00 00 00 02
					D0 C0

					15 01 00 00 00 00 02
					D0 16

					15 01 00 00 00 00 02
					D0 03

					15 01 00 00 00 00 02
					D0 1A

					15 01 00 00 00 00 02
					D0 40

					15 01 00 00 00 00 02
					D0 80

					15 01 00 00 00 00 02
					D0 F0

					15 01 00 00 00 00 02
					D0 14

					15 01 00 00 00 00 02
					D0 02

					15 01 00 00 00 00 02
					D0 20

					15 01 00 00 00 00 02
					D0 80

					15 01 00 00 00 00 02
					D0 F0

					15 01 00 00 00 00 02
					D0 13

					15 01 00 00 00 00 02
					D0 01

					15 01 00 00 00 00 02
					D0 24

					15 01 00 00 00 00 02
					D0 A4

					15 01 00 00 00 00 02
					D0 11

					15 01 00 00 00 00 02
					D0 02

					15 01 00 00 00 00 02
					D0 26

					15 01 00 00 00 00 02
					D0 40

					15 01 00 00 00 00 02
					D0 C0

					15 01 00 00 00 00 02
					D0 10

					15 01 00 00 00 00 02
					D0 01

					15 01 00 00 00 00 02
					D0 2A

					15 01 00 00 00 00 02
					D0 A4

					15 01 00 00 00 00 02
					D0 0E

					15 01 00 00 00 00 02
					D0 02

					15 01 00 00 00 00 02
					D0 2C

					15 01 00 00 00 00 02
					D0 40

					15 01 00 00 00 00 02
					D0 C0

					15 01 00 00 00 00 02
					D0 0D

					15 01 00 00 00 00 02
					D0 02

					15 01 00 00 00 00 02
					D0 2E

					15 01 00 00 00 00 02
					D0 40

					15 01 00 00 00 00 02
					D0 C0

					15 01 00 00 00 00 02
					D0 0C

					15 01 00 00 00 00 02
					D0 02

					15 01 00 00 00 00 02
					D0 30

					15 01 00 00 00 00 02
					D0 40

					15 01 00 00 00 00 02
					D0 C0

					15 01 00 00 00 00 02
					D0 0B

					15 01 00 00 00 00 02
					D0 01

					15 01 00 00 00 00 02
					D0 34

					15 01 00 00 00 00 02
					D0 C0

					15 01 00 00 00 00 02
					D0 0A

					15 01 00 00 00 00 02
					D0 02

					15 01 00 00 00 00 02
					D0 34

					15 01 00 00 00 00 02
					D0 40

					15 01 00 00 00 00 02
					D0 C0

					15 01 00 00 00 00 02
					D0 0A

					15 01 00 00 00 00 02
					D0 01

					15 01 00 00 00 00 02
					D0 36

					15 01 00 00 00 00 02
					D0 40

					15 01 00 00 00 00 02
					D0 09

					15 01 00 00 00 00 02
					D0 01

					15 01 00 00 00 00 02
					D0 38

					15 01 00 00 00 00 02
					D0 40

					15 01 00 00 00 00 02
					D0 08

					15 01 00 00 00 00 02
					D0 01

					15 01 00 00 00 00 02
					D0 3A

					15 01 00 00 00 00 02
					D0 C0

					15 01 00 00 00 00 02
					D0 08

					15 01 00 00 00 00 02
					D0 01

					15 01 00 00 00 00 02
					D0 3A

					15 01 00 00 00 00 02
					D0 40

					15 01 00 00 00 00 02
					D0 07

					15 01 00 00 00 00 02
					D0 01

					15 01 00 00 00 00 02
					D0 3C

					15 01 00 00 00 00 02
					D0 40

					15 01 00 00 00 00 02
					D0 06

					15 01 00 00 00 00 02
					D0 01

					15 01 00 00 00 00 02
					D0 3E

					15 01 00 00 00 00 02
					D0 4A

					15 01 00 00 00 00 02
					D0 05

					15 01 00 00 00 00 02
					D0 02

					15 01 00 00 00 00 02
					D0 3E

					15 01 00 00 00 00 02
					D0 40

					15 01 00 00 00 00 02
					D0 A4

					15 01 00 00 00 00 02
					D0 05

					15 01 00 00 00 00 02
					D0 01

					15 01 00 00 00 00 02
					D0 40

					15 01 00 00 00 00 02
					D0 40

					15 01 00 00 00 00 02
					D0 04

					15 01 00 00 00 00 02
					D0 02

					15 01 00 00 00 00 02
					D0 40

					15 01 00 00 00 00 02
					D0 40

					15 01 00 00 00 00 02
					D0 C0

					15 01 00 00 00 00 02
					D0 04

					15 01 00 00 00 00 02
					D0 01

					15 01 00 00 00 00 02
					D0 42

					15 01 00 00 00 00 02
					D0 80

					15 01 00 00 00 00 02
					D0 04

					15 01 00 00 00 00 02
					D0 01

					15 01 00 00 00 00 02
					D0 42

					15 01 00 00 00 00 02
					D0 40

					15 01 00 00 00 00 02
					D0 03

					15 01 00 00 00 00 02
					D0 01

					15 01 00 00 00 00 02
					D0 44

					15 01 00 00 00 00 02
					D0 C0

					15 01 00 00 00 00 02
					D0 03

					15 01 00 00 00 00 02
					D0 01

					15 01 00 00 00 00 02
					D0 44

					15 01 00 00 00 00 02
					D0 40

					15 01 00 00 00 00 02
					D0 03

					15 01 00 00 00 00 02
					D0 00

					15 01 00 00 00 00 02
					D0 46

					15 01 00 00 00 00 02
					D0 02

					15 01 00 00 00 00 02
					D0 01

					15 01 00 00 00 00 02
					D0 46

					15 01 00 00 00 00 02
					D0 C0

					15 01 00 00 00 00 02
					D0 02

					15 01 00 00 00 00 02
					D0 01

					15 01 00 00 00 00 02
					D0 46

					15 01 00 00 00 00 02
					D0 80

					15 01 00 00 00 00 02
					D0 02

					15 01 00 00 00 00 02
					D0 00

					15 01 00 00 00 00 02
					D0 48

					15 01 00 00 00 00 02
					D0 01

					15 01 00 00 00 00 02
					D0 01

					15 01 00 00 00 00 02
					D0 48

					15 01 00 00 00 00 02
					D0 C0

					15 01 00 00 00 00 02
					D0 01

					15 01 00 00 00 00 02
					D0 01

					15 01 00 00 00 00 02
					D0 48

					15 01 00 00 00 00 02
					D0 C0

					15 01 00 00 00 00 02
					D0 01

					15 01 00 00 00 00 02
					D0 01

					15 01 00 00 00 00 02
					D0 48

					15 01 00 00 00 00 02
					D0 C0

					15 01 00 00 00 00 02
					D0 01

					15 01 00 00 00 00 02
					D0 01

					15 01 00 00 00 00 02
					D0 48

					15 01 00 00 00 00 02
					D0 A4

					15 01 00 00 00 00 02
					D0 01

					15 01 00 00 00 00 02
					D0 01

					15 01 00 00 00 00 02
					D0 48

					15 01 00 00 00 00 02
					D0 A4

					15 01 00 00 00 00 02
					D0 01

					15 01 00 00 00 00 02
					D0 01

					15 01 00 00 00 00 02
					D0 48

					15 01 00 00 00 00 02
					D0 80

					15 01 00 00 00 00 02
					D0 01

					15 01 00 00 00 00 02
					D0 01

					15 01 00 00 00 00 02
					D0 48

					15 01 00 00 00 00 02
					D0 80

					15 01 00 00 00 00 02
					D0 01

					15 01 00 00 00 00 02
					D0 01

					15 01 00 00 00 00 02
					D0 48

					15 01 00 00 00 00 02
					D0 80

					15 01 00 00 00 00 02
					D0 01

					15 01 00 00 00 00 02
					D0 01

					15 01 00 00 00 00 02
					D0 48

					15 01 00 00 00 00 02
					D0 A4

					15 01 00 00 00 00 02
					D0 01

					15 01 00 00 00 00 02
					D0 01

					15 01 00 00 00 00 02
					D0 48

					15 01 00 00 00 00 02
					D0 A4

					15 01 00 00 00 00 02
					D0 01

					15 01 00 00 00 00 02
					D0 01

					15 01 00 00 00 00 02
					D0 48

					15 01 00 00 00 00 02
					D0 A4

					15 01 00 00 00 00 02
					D0 01

					15 01 00 00 00 00 02
					D0 01

					15 01 00 00 00 00 02
					D0 48

					15 01 00 00 00 00 02
					D0 C0

					15 01 00 00 00 00 02
					D0 01

					15 01 00 00 00 00 02
					D0 01

					15 01 00 00 00 00 02
					D0 48

					15 01 00 00 00 00 02
					D0 C0

					15 01 00 00 00 00 02
					D0 01

					15 01 00 00 00 00 02
					D0 01

					15 01 00 00 00 00 02
					D0 48

					15 01 00 00 00 00 02
					D0 C0

					15 01 00 00 00 00 02
					D0 02

					15 01 00 00 00 00 02
					D0 00

					15 01 00 00 00 00 02
					D0 48

					15 01 00 00 00 00 02
					D0 02

					15 01 00 00 00 00 02
					D0 01

					15 01 00 00 00 00 02
					D0 46

					15 01 00 00 00 00 02
					D0 80

					15 01 00 00 00 00 02
					D0 02

					15 01 00 00 00 00 02
					D0 01

					15 01 00 00 00 00 02
					D0 46

					15 01 00 00 00 00 02
					D0 C0

					15 01 00 00 00 00 02
					D0 03

					15 01 00 00 00 00 02
					D0 00

					15 01 00 00 00 00 02
					D0 46

					15 01 00 00 00 00 02
					D0 03

					15 01 00 00 00 00 02
					D0 01

					15 01 00 00 00 00 02
					D0 44

					15 01 00 00 00 00 02
					D0 40

					15 01 00 00 00 00 02
					D0 03

					15 01 00 00 00 00 02
					D0 01

					15 01 00 00 00 00 02
					D0 44

					15 01 00 00 00 00 02
					D0 A4

					15 01 00 00 00 00 02
					D0 04

					15 01 00 00 00 00 02
					D0 01

					15 01 00 00 00 00 02
					D0 42

					15 01 00 00 00 00 02
					D0 40

					15 01 00 00 00 00 02
					D0 04

					15 01 00 00 00 00 02
					D0 01

					15 01 00 00 00 00 02
					D0 42

					15 01 00 00 00 00 02
					D0 80

					15 01 00 00 00 00 02
					D0 04

					15 01 00 00 00 00 02
					D0 01

					15 01 00 00 00 00 02
					D0 42

					15 01 00 00 00 00 02
					D0 F0

					15 01 00 00 00 00 02
					D0 05

					15 01 00 00 00 00 02
					D0 01

					15 01 00 00 00 00 02
					D0 40

					15 01 00 00 00 00 02
					D0 80

					15 01 00 00 00 00 02
					D0 05

					15 01 00 00 00 00 02
					D0 01

					15 01 00 00 00 00 02
					D0 40

					15 01 00 00 00 00 02
					D0 F0

					15 01 00 00 00 00 02
					D0 06

					15 01 00 00 00 00 02
					D0 01

					15 01 00 00 00 00 02
					D0 3E

					15 01 00 00 00 00 02
					D0 80

					15 01 00 00 00 00 02
					D0 07

					15 01 00 00 00 00 02
					D0 01

					15 01 00 00 00 00 02
					D0 3C

					15 01 00 00 00 00 02
					D0 40

					15 01 00 00 00 00 02
					D0 07

					15 01 00 00 00 00 02
					D0 01

					15 01 00 00 00 00 02
					D0 3C

					15 01 00 00 00 00 02
					D0 C0

					15 01 00 00 00 00 02
					D0 08

					15 01 00 00 00 00 02
					D0 01

					15 01 00 00 00 00 02
					D0 3A

					15 01 00 00 00 00 02
					D0 80

					15 01 00 00 00 00 02
					D0 09

					15 01 00 00 00 00 02
					D0 01

					15 01 00 00 00 00 02
					D0 38

					15 01 00 00 00 00 02
					D0 40

					15 01 00 00 00 00 02
					D0 09

					15 01 00 00 00 00 02
					D0 02

					15 01 00 00 00 00 02
					D0 36

					15 01 00 00 00 00 02
					D0 40

					15 01 00 00 00 00 02
					D0 C0

					15 01 00 00 00 00 02
					D0 0A

					15 01 00 00 00 00 02
					D0 02

					15 01 00 00 00 00 02
					D0 34

					15 01 00 00 00 00 02
					D0 40

					15 01 00 00 00 00 02
					D0 80

					15 01 00 00 00 00 02
					D0 0B

					15 01 00 00 00 00 02
					D0 01

					15 01 00 00 00 00 02
					D0 34

					15 01 00 00 00 00 02
					D0 C0

					15 01 00 00 00 00 02
					D0 0C

					15 01 00 00 00 00 02
					D0 01 //

					15 01 00 00 00 00 02
					D0 32

					15 01 00 00 00 00 02
					D0 C0

					15 01 00 00 00 00 02
					D0 0D

					15 01 00 00 00 00 02
					D0 02

					15 01 00 00 00 00 02
					D0 2E

					15 01 00 00 00 00 02
					D0 40

					15 01 00 00 00 00 02
					D0 C0

					15 01 00 00 00 00 02
					D0 0E

					15 01 00 00 00 00 02
					D0 02

					15 01 00 00 00 00 02
					D0 2C

					15 01 00 00 00 00 02
					D0 40

					15 01 00 00 00 00 02
					D0 C0

					15 01 00 00 00 00 02
					D0 10

					15 01 00 00 00 00 02
					D0 01

					15 01 00 00 00 00 02
					D0 2A

					15 01 00 00 00 00 02
					D0 80

					15 01 00 00 00 00 02
					D0 11

					15 01 00 00 00 00 02
					D0 02

					15 01 00 00 00 00 02
					D0 26

					15 01 00 00 00 00 02
					D0 40

					15 01 00 00 00 00 02
					D0 C0

					15 01 00 00 00 00 02
					D0 13

					15 01 00 00 00 00 02
					D0 01

					15 01 00 00 00 00 02
					D0 24

					15 01 00 00 00 00 02
					D0 80

					15 01 00 00 00 00 02
					D0 14

					15 01 00 00 00 00 02
					D0 02 //

					15 01 00 00 00 00 02
					D0 20

					15 01 00 00 00 00 02
					D0 80

					15 01 00 00 00 00 02
					D0 F0

					15 01 00 00 00 00 02
					D0 16

					15 01 00 00 00 00 02
					D0 02

					15 01 00 00 00 00 02
					D0 1C

					15 01 00 00 00 00 02
					D0 80

					15 01 00 00 00 00 02
					D0 F0

					15 01 00 00 00 00 02
					D0 19

					15 01 00 00 00 00 02
					D0 02

					15 01 00 00 00 00 02
					D0 16

					15 01 00 00 00 00 02
					D0 40

					15 01 00 00 00 00 02
					D0 C0

					15 01 00 00 00 00 02
					D0 1C

					15 01 00 00 00 00 02
					D0 03

					15 01 00 00 00 00 02
					D0 0E

					15 01 00 00 00 00 02
					D0 40

					15 01 00 00 00 00 02
					D0 80

					15 01 00 00 00 00 02
					D0 C0

					15 01 00 00 00 00 02
					D0 1F

					15 01 00 00 00 00 02
					D0 07

					15 01 00 00 00 00 02
					D0 00

					15 01 00 00 00 00 02
					D0 80

					15 01 00 00 00 00 02
					D0 80

					15 01 00 00 00 00 02
					D0 A4

					15 01 00 00 00 00 02
					D0 A4

					15 01 00 00 00 00 02
					D0 C0

					15 01 00 00 00 00 02
					D0 C0

					15 01 00 00 00 00 02
					D0 C0

					15 01 00 00 00 00 02
					BD 00

					15 01 00 00 00 00 02
					D0 31

					05 01 00 00 64 00 01 // Sleep out
					11

					05 01 00 00 0A 00 01 // Display on
					29

					39 01 00 00 00 00 03 // 56 - Set CABC Manual brightness
					51 0F FF

					39 01 00 00 00 00 03 // 57 - Set CABC Minimum brightness
					5E 00 3D

					39 01 00 00 00 00 06 // 58 - Set PWM Frequency to 20kHz
					C9 00 1E 0E B0 01

					15 01 00 00 00 00 02 // 59 - Set CABC mode to UI mode
					55 01

					15 01 00 00 00 00 02 // 59 - Set to Bank3
					BD 03

					39 01 00 00 00 00 0B // 57 - PWM duty is 70% for UI mode
					E4 CD CD CD A7 A7 A7 C3 C3 C3 EA

					15 01 00 00 00 00 02 // 59 - Set to Bank0
					BD 00

					15 01 00 00 00 00 02 // 60 - Enable Backlight Control
					53 24
				];
				qcom,mdss-dsi-on-command-state = "dsi_lp_mode";

				qcom,mdss-dsi-off-command = [
					05 01 00 00 14 00 01 // Display off
					28

					05 01 00 00 46 00 01 // Sleep in
					10
				];
				qcom,mdss-dsi-off-command-state = "dsi_hs_mode";
			};
		};
	};
};

&sde_dsi  {
	qcom,dsi-default-panel = <&dsi_hx83113a_fhd_vdo>;
};

/* SE 4 pin mappings for DW8768 */
&qupv3_se4_i2c {
	dw8768@3e {
		compatible = "dw8768";
		status="okay";
		reg = <0x3e>;
	};
};

&pm8150l_lcdb {
    status = "okay";
};

&pm8150a_amoled {
    status = "disabled";
};

&pm8150l_wled {
	qcom,string-cfg= <7>;
	qcom,leds-per-string = <7>;
	qcom,fs-current-limit = <20000>;
	qcom,cabc-sel = <1>;
	qcom,en-cabc;
    status = "okay";
};

&mdss_dsi1 {
	status = "disabled";
};
